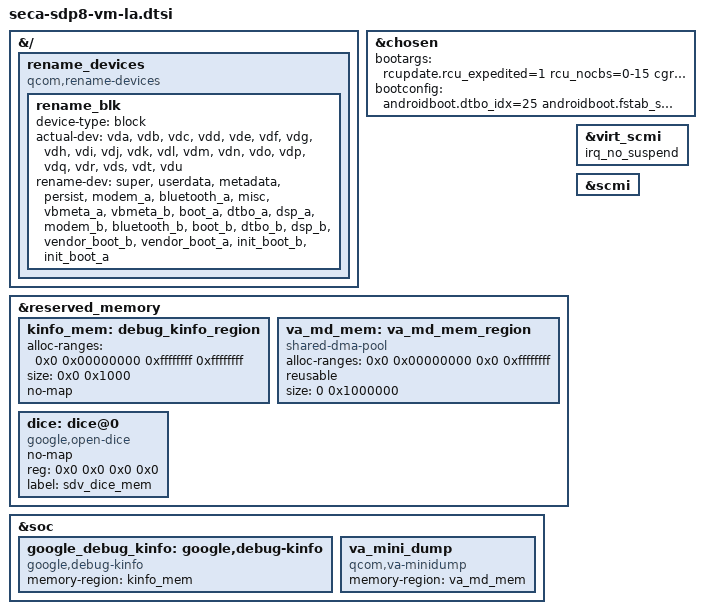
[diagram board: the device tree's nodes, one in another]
// SPDX-License-Identifier: BSD-3-Clause
/*
 * Copyright (c) Qualcomm Technologies, Inc. and/or its subsidiaries.
 */

&{/} {
	rename_devices: rename_devices {
		compatible = "qcom,rename-devices";
		rename_blk: rename_blk {
			device-type = "block";
			actual-dev = "vda", "vdb", "vdc",
					"vdd", "vde", "vdf",
					"vdg", "vdh", "vdi",
					"vdj", "vdk", "vdl",
					"vdm", "vdn", "vdo",
					"vdp", "vdq", "vdr",
					"vds", "vdt", "vdu";
			rename-dev = "super", "userdata", "metadata",
					"persist", "modem_a","bluetooth_a",
					"misc", "vbmeta_a", "vbmeta_b",
					"boot_a", "dtbo_a", "dsp_a",
					"modem_b", "bluetooth_b", "boot_b",
					"dtbo_b", "dsp_b", "vendor_boot_b",
					"vendor_boot_a", "init_boot_b", "init_boot_a";
		};
	};
};

&chosen {
	bootargs = "rcupdate.rcu_expedited=1 rcu_nocbs=0-15 cgroup.memory=nokmem,nosocket kpti=0 ufshcd-core.use_mcq_mode=n qcom_dma_heaps.enable_bitstream_contig_heap=y arm64.nopauth kasan=off msm_show_resume_irq.debug_mask=1 fw_devlink.strict=1 driver_async_probe=arm-scmi";
	bootconfig = "androidboot.dtbo_idx=25 androidboot.fstab_suffix=hqx.seca.qcom";
};

&reserved_memory {
	kinfo_mem: debug_kinfo_region {
		alloc-ranges = <0x0 0x00000000 0xffffffff 0xffffffff>;
		size = <0x0 0x1000>;
		no-map;
	};

	va_md_mem: va_md_mem_region {
		compatible = "shared-dma-pool";
		alloc-ranges = <0x0 0x00000000 0x0 0xffffffff>;
		reusable;
		size = <0 0x1000000>;
	};

	dice: dice@0 {
		compatible = "google,open-dice";
		no-map;
		reg = <0x0 0x0 0x0 0x0>;
		label = "sdv_dice_mem";
	};
};

&soc {
	google_debug_kinfo: google,debug-kinfo {
		compatible = "google,debug-kinfo";
		memory-region = <&kinfo_mem>;
	};

	va_mini_dump: va_mini_dump {
		compatible = "qcom,va-minidump";
		memory-region = <&va_md_mem>;
	};
};

&virt_scmi {
	irq_no_suspend;
	status = "ok";
};

&scmi {
	status = "ok";
};
